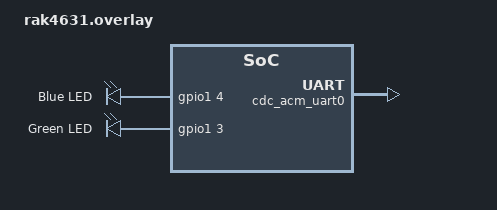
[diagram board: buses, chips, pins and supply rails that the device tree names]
/ {
	chosen {
		zephyr,console = &cdc_acm_uart0;
		zephyr,shell-uart = &cdc_acm_uart0;
	};

	aliases {
		blue-led = &blue_led;
		green-led = &green_led;
	};

	leds {
		compatible = "gpio-leds";
		blue_led: led_2 {
			gpios = <&gpio1 4 GPIO_ACTIVE_HIGH>;
			label = "Blue LED";
		};
		green_led: led_1 {
			gpios = <&gpio1 3 GPIO_ACTIVE_HIGH>;
			label = "Green LED";
		};
	};
};

&zephyr_udc0 {
	cdc_acm_uart0: cdc_acm_uart0 {
		compatible = "zephyr,cdc-acm-uart";
	};
};
